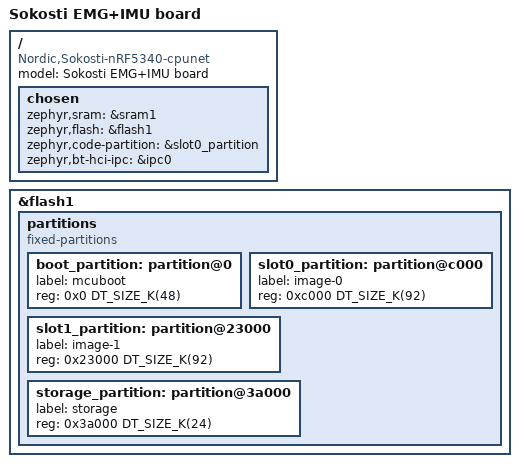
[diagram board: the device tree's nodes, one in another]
/dts-v1/;

#include <nordic/nrf5340_cpunet_qkaa.dtsi>
#include "Sokosti_nRF5340-pinctrl.dtsi"

/ {
	model = "Sokosti EMG+IMU board";
	compatible = "Nordic,Sokosti-nRF5340-cpunet";

	chosen {
		zephyr,sram = &sram1;
		zephyr,flash = &flash1;
		zephyr,code-partition = &slot0_partition;
		zephyr,bt-hci-ipc = &ipc0;
	};
};

&flash1 {
	partitions {
		compatible = "fixed-partitions";
		#address-cells = <1>;
		#size-cells = <1>;

		boot_partition: partition@0 {
			label = "mcuboot";
			reg = <0x0 DT_SIZE_K(48)>;
		};

		slot0_partition: partition@c000 {
			label = "image-0";
			reg = <0xc000 DT_SIZE_K(92)>;
		};

		slot1_partition: partition@23000 {
			label = "image-1";
			reg = <0x23000 DT_SIZE_K(92)>;
		};

		storage_partition: partition@3a000 {
			label = "storage";
			reg = <0x3a000 DT_SIZE_K(24)>;
		};
	};
};

#include "Sokosti_nRF5340-shared_sram.dtsi"
